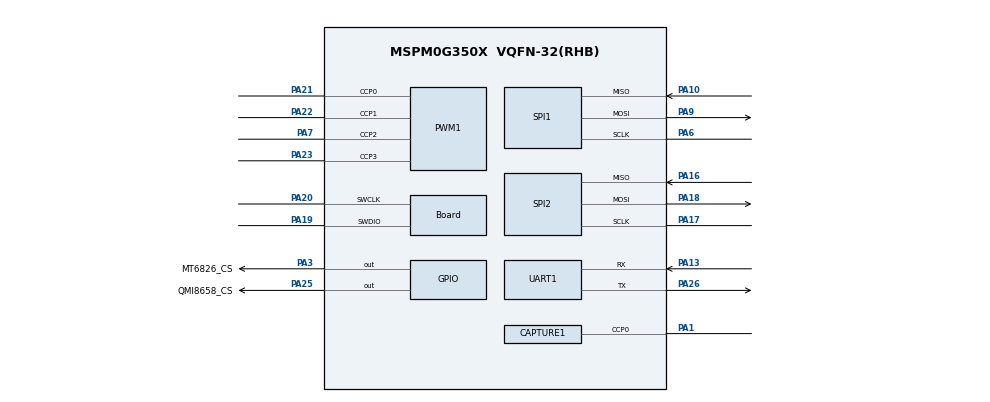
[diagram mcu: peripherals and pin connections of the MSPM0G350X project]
/**
 * @cliArgs --device "MSPM0G350X" --part "Default" --package "VQFN-32(RHB)" --product "mspm0_sdk@2.08.00.03"
 * @versions {"tool":"1.25.0+4268"}
 */

/**
 * Import the modules used in this configuration.
 */
const ADC12    = scripting.addModule("/ti/driverlib/ADC12", {}, false);
const ADC121   = ADC12.addInstance();
const ADC122   = ADC12.addInstance();
const Board    = scripting.addModule("/ti/driverlib/Board");
const CAPTURE  = scripting.addModule("/ti/driverlib/CAPTURE", {}, false);
const CAPTURE1 = CAPTURE.addInstance();
const DMA      = scripting.addModule("/ti/driverlib/DMA");
const GPIO     = scripting.addModule("/ti/driverlib/GPIO", {}, false);
const GPIO1    = GPIO.addInstance();
const PWM      = scripting.addModule("/ti/driverlib/PWM", {}, false);
const PWM1     = PWM.addInstance();
const SPI      = scripting.addModule("/ti/driverlib/SPI", {}, false);
const SPI1     = SPI.addInstance();
const SPI2     = SPI.addInstance();
const SYSCTL   = scripting.addModule("/ti/driverlib/SYSCTL");
const TIMER    = scripting.addModule("/ti/driverlib/TIMER", {}, false);
const TIMER1   = TIMER.addInstance();
const TIMER2   = TIMER.addInstance();
const UART     = scripting.addModule("/ti/driverlib/UART", {}, false);
const UART1    = UART.addInstance();

/**
 * Write custom configuration values to the imported modules.
 */
const divider9       = system.clockTree["UDIV"];
divider9.divideValue = 2;

const multiplier2         = system.clockTree["PLL_QDIV"];
multiplier2.multiplyValue = 5;

const mux8       = system.clockTree["HSCLKMUX"];
mux8.inputSelect = "HSCLKMUX_SYSPLL0";

ADC121.endAdd                            = 1;
ADC121.trigSrc                           = "DL_ADC12_TRIG_SRC_EVENT";
ADC121.$name                             = "ADC_V";
ADC121.repeatMode                        = true;
ADC121.enabledInterrupts                 = ["DL_ADC12_INTERRUPT_DMA_DONE"];
ADC121.adcMem0trig                       = "DL_ADC12_TRIGGER_MODE_TRIGGER_NEXT";
ADC121.subChanID                         = 1;
ADC121.powerDownMode                     = "DL_ADC12_POWER_DOWN_MODE_MANUAL";
ADC121.sampleTime0                       = "250 ns";
ADC121.configureDMA                      = true;
ADC121.sampCnt                           = 1;
ADC121.enabledDMATriggers                = ["DL_ADC12_DMA_MEM0_RESULT_LOADED"];
ADC121.peripheral.$assign                = "ADC0";
ADC121.peripheral.adcPin0.$assign        = "PA27";
ADC121.adcPin0Config.hideOutputInversion = scripting.forceWrite(false);
ADC121.adcPin0Config.$name               = "ti_driverlib_gpio_GPIOPinGeneric8";
ADC121.DMA_CHANNEL.addressMode           = "f2b";
ADC121.DMA_CHANNEL.srcLength             = "HALF_WORD";
ADC121.DMA_CHANNEL.dstLength             = "HALF_WORD";
ADC121.DMA_CHANNEL.configureTransferSize = true;
ADC121.DMA_CHANNEL.transferMode          = "FULL_CH_REPEAT_SINGLE";
ADC121.DMA_CHANNEL.$name                 = "DMA_CH1";

ADC122.trigSrc                           = "DL_ADC12_TRIG_SRC_EVENT";
ADC122.$name                             = "ADC_U";
ADC122.repeatMode                        = true;
ADC122.adcMem0trig                       = "DL_ADC12_TRIGGER_MODE_TRIGGER_NEXT";
ADC122.subChanID                         = 2;
ADC122.powerDownMode                     = "DL_ADC12_POWER_DOWN_MODE_MANUAL";
ADC122.sampleTime0                       = "250ns";
ADC122.configureDMA                      = true;
ADC122.sampCnt                           = 1;
ADC122.enabledDMATriggers                = ["DL_ADC12_DMA_MEM0_RESULT_LOADED"];
ADC122.enabledInterrupts                 = ["DL_ADC12_INTERRUPT_DMA_DONE"];
ADC122.peripheral.$assign                = "ADC1";
ADC122.peripheral.adcPin0.$assign        = "PA15";
ADC122.adcPin0Config.hideOutputInversion = scripting.forceWrite(false);
ADC122.adcPin0Config.$name               = "ti_driverlib_gpio_GPIOPinGeneric13";
ADC122.DMA_CHANNEL.$name                 = "DMA_CH0";
ADC122.DMA_CHANNEL.srcLength             = "HALF_WORD";
ADC122.DMA_CHANNEL.dstLength             = "HALF_WORD";
ADC122.DMA_CHANNEL.configureTransferSize = true;
ADC122.DMA_CHANNEL.transferMode          = "FULL_CH_REPEAT_SINGLE";
ADC122.DMA_CHANNEL.addressMode           = "f2b";

Board.peripheral.$assign          = "DEBUGSS";
Board.peripheral.swclkPin.$assign = "PA20";
Board.peripheral.swdioPin.$assign = "PA19";

CAPTURE1.$name                              = "CAPTURE_Angle";
CAPTURE1.interrupts                         = ["CC0_DN"];
CAPTURE1.interruptPriority                  = "1";
CAPTURE1.captMode                           = "PULSE_WIDTH";
CAPTURE1.timerPeriod                        = "2ms";
CAPTURE1.peripheral.$assign                 = "TIMG8";
CAPTURE1.peripheral.ccp0Pin.$assign         = "PA1";
CAPTURE1.ccp0PinConfig.hideOutputInversion  = scripting.forceWrite(false);
CAPTURE1.ccp0PinConfig.onlyInternalResistor = scripting.forceWrite(false);
CAPTURE1.ccp0PinConfig.passedPeripheralType = scripting.forceWrite("Digital");
CAPTURE1.ccp0PinConfig.$name                = "ti_driverlib_gpio_GPIOPinGeneric11";

GPIO1.port                           = "PORTA";
GPIO1.$name                          = "SPI_CS";
GPIO1.associatedPins.create(2);
GPIO1.associatedPins[0].$name        = "QMI8658_CS";
GPIO1.associatedPins[0].initialValue = "SET";
GPIO1.associatedPins[0].ioStructure  = "SD";
GPIO1.associatedPins[0].assignedPin  = "25";
GPIO1.associatedPins[0].pin.$assign  = "PA25";
GPIO1.associatedPins[1].assignedPin  = "3";
GPIO1.associatedPins[1].$name        = "MT6826_CS";
GPIO1.associatedPins[1].ioStructure  = "SD";
GPIO1.associatedPins[1].initialValue = "SET";
GPIO1.associatedPins[1].pin.$assign  = "PA3";

PWM1.pwmMode                            = "CENTER_ALIGN";
PWM1.timerCount                         = 1024;
PWM1.$name                              = "PWM_Motor_Control";
PWM1.ccIndex                            = [0,1,2,3];
PWM1.event1PublisherChannel             = 2;
PWM1.event2PublisherChannel             = 1;
PWM1.event2ControllerInterruptEn        = ["CC2_UP_EVENT"];
PWM1.event1ControllerInterruptEn        = ["CC2_UP_EVENT"];
PWM1.PWM_CHANNEL_0.$name                = "ti_driverlib_pwm_PWMTimerCC0";
PWM1.PWM_CHANNEL_1.$name                = "ti_driverlib_pwm_PWMTimerCC1";
PWM1.ccp0PinConfig.direction            = scripting.forceWrite("OUTPUT");
PWM1.ccp0PinConfig.hideOutputInversion  = scripting.forceWrite(false);
PWM1.ccp0PinConfig.onlyInternalResistor = scripting.forceWrite(false);
PWM1.ccp0PinConfig.passedPeripheralType = scripting.forceWrite("Digital");
PWM1.ccp0PinConfig.$name                = "ti_driverlib_gpio_GPIOPinGeneric7";
PWM1.ccp1PinConfig.direction            = scripting.forceWrite("OUTPUT");
PWM1.ccp1PinConfig.hideOutputInversion  = scripting.forceWrite(false);
PWM1.ccp1PinConfig.onlyInternalResistor = scripting.forceWrite(false);
PWM1.ccp1PinConfig.passedPeripheralType = scripting.forceWrite("Digital");
PWM1.ccp1PinConfig.$name                = "ti_driverlib_gpio_GPIOPinGeneric9";
PWM1.peripheral.$assign                 = "TIMA0";
PWM1.peripheral.ccp0Pin.$assign         = "PA21";
PWM1.peripheral.ccp1Pin.$assign         = "PA22";
PWM1.peripheral.ccp2Pin.$assign         = "PA7";
PWM1.peripheral.ccp3Pin.$assign         = "PA23";
PWM1.PWM_CHANNEL_2.$name                = "ti_driverlib_pwm_PWMTimerCC3";
PWM1.PWM_CHANNEL_2.ccValue              = 511;
PWM1.PWM_CHANNEL_3.$name                = "ti_driverlib_pwm_PWMTimerCC2";
PWM1.ccp2PinConfig.$name                = "ti_driverlib_gpio_GPIOPinGeneric3";
PWM1.ccp3PinConfig.$name                = "ti_driverlib_gpio_GPIOPinGeneric10";

SPI1.$name                              = "MT6826";
SPI1.chipSelect                         = ["1"];
SPI1.frameFormat                        = "MOTO3";
SPI1.polarity                           = "1";
SPI1.phase                              = "1";
SPI1.targetBitRate                      = 4000000;
SPI1.sclkPinConfig.direction            = scripting.forceWrite("OUTPUT");
SPI1.sclkPinConfig.onlyInternalResistor = scripting.forceWrite(false);
SPI1.sclkPinConfig.passedPeripheralType = scripting.forceWrite("Digital");
SPI1.sclkPinConfig.$name                = "ti_driverlib_gpio_GPIOPinGeneric0";
SPI1.sclkPinConfig.enableConfig         = true;
SPI1.sclkPinConfig.internalResistor     = "PULL_UP";
SPI1.mosiPinConfig.direction            = scripting.forceWrite("OUTPUT");
SPI1.mosiPinConfig.hideOutputInversion  = scripting.forceWrite(false);
SPI1.mosiPinConfig.onlyInternalResistor = scripting.forceWrite(false);
SPI1.mosiPinConfig.passedPeripheralType = scripting.forceWrite("Digital");
SPI1.mosiPinConfig.$name                = "ti_driverlib_gpio_GPIOPinGeneric1";
SPI1.mosiPinConfig.enableConfig         = true;
SPI1.mosiPinConfig.internalResistor     = "PULL_UP";
SPI1.misoPinConfig.onlyInternalResistor = scripting.forceWrite(false);
SPI1.misoPinConfig.passedPeripheralType = scripting.forceWrite("Digital");
SPI1.misoPinConfig.$name                = "ti_driverlib_gpio_GPIOPinGeneric2";
SPI1.misoPinConfig.enableConfig         = true;
SPI1.misoPinConfig.internalResistor     = "PULL_UP";
SPI1.peripheral.$assign                 = "SPI0";
SPI1.peripheral.sclkPin.$assign         = "PA6";
SPI1.peripheral.mosiPin.$assign         = "PA9";
SPI1.peripheral.misoPin.$assign         = "PA10";

SPI2.$name                              = "QMI8658";
SPI2.rxFifoThreshold                    = "DL_SPI_RX_FIFO_LEVEL_ONE_FRAME";
SPI2.txFifoThreshold                    = "DL_SPI_TX_FIFO_LEVEL_EMPTY";
SPI2.chipSelect                         = ["3"];
SPI2.frameFormat                        = "MOTO3";
SPI2.targetBitRate                      = 4000000;
SPI2.sclkPinConfig.direction            = scripting.forceWrite("OUTPUT");
SPI2.sclkPinConfig.onlyInternalResistor = scripting.forceWrite(false);
SPI2.sclkPinConfig.passedPeripheralType = scripting.forceWrite("Digital");
SPI2.sclkPinConfig.$name                = "ti_driverlib_gpio_GPIOPinGeneric4";
SPI2.sclkPinConfig.enableConfig         = true;
SPI2.sclkPinConfig.internalResistor     = "PULL_UP";
SPI2.mosiPinConfig.direction            = scripting.forceWrite("OUTPUT");
SPI2.mosiPinConfig.hideOutputInversion  = scripting.forceWrite(false);
SPI2.mosiPinConfig.onlyInternalResistor = scripting.forceWrite(false);
SPI2.mosiPinConfig.passedPeripheralType = scripting.forceWrite("Digital");
SPI2.mosiPinConfig.$name                = "ti_driverlib_gpio_GPIOPinGeneric5";
SPI2.mosiPinConfig.enableConfig         = true;
SPI2.mosiPinConfig.internalResistor     = "PULL_UP";
SPI2.misoPinConfig.onlyInternalResistor = scripting.forceWrite(false);
SPI2.misoPinConfig.passedPeripheralType = scripting.forceWrite("Digital");
SPI2.misoPinConfig.$name                = "ti_driverlib_gpio_GPIOPinGeneric6";
SPI2.misoPinConfig.enableConfig         = true;
SPI2.misoPinConfig.internalResistor     = "PULL_UP";
SPI2.peripheral.$assign                 = "SPI1";
SPI2.peripheral.sclkPin.$assign         = "PA17";
SPI2.peripheral.mosiPin.$assign         = "PA18";
SPI2.peripheral.misoPin.$assign         = "PA16";


TIMER1.timerPeriod       = "1ms";
TIMER1.$name             = "SystemTick";
TIMER1.timerMode         = "PERIODIC_UP";
TIMER1.interrupts        = ["ZERO"];
TIMER1.interruptPriority = "1";

TIMER2.timerStartTimer  = true;
TIMER2.timerClkDiv      = 8;
TIMER2.timerClkPrescale = 200;
TIMER2.timerMode        = "PERIODIC_UP";
TIMER2.timerPeriod      = "1s";
TIMER2.$name            = "TIMER_50US";

UART1.$name                    = "UART_0";
UART1.enabledInterrupts        = ["RX"];
UART1.peripheral.$assign       = "UART3";
UART1.peripheral.rxPin.$assign = "PA13";
UART1.peripheral.txPin.$assign = "PA26";
UART1.txPinConfig.$name        = "ti_driverlib_gpio_GPIOPinGeneric14";
UART1.rxPinConfig.$name        = "ti_driverlib_gpio_GPIOPinGeneric15";

/**
 * Pinmux solution for unlocked pins/peripherals. This ensures that minor changes to the automatic solver in a future
 * version of the tool will not impact the pinmux you originally saw.  These lines can be completely deleted in order to
 * re-solve from scratch.
 */
ADC121.DMA_CHANNEL.peripheral.$suggestSolution = "DMA_CH1";
ADC122.DMA_CHANNEL.peripheral.$suggestSolution = "DMA_CH0";
SYSCTL.peripheral.$suggestSolution             = "SYSCTL";
TIMER1.peripheral.$suggestSolution             = "TIMG0";
TIMER2.peripheral.$suggestSolution             = "TIMA1";
